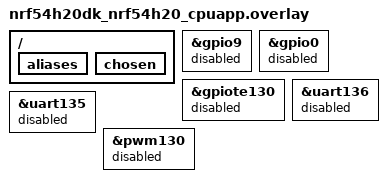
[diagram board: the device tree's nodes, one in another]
/*
 * Copyright (c) 2024 Nordic Semiconductor ASA
 *
 * SPDX-License-Identifier: LicenseRef-Nordic-5-Clause
 */


/delete-node/ &led0;
/delete-node/ &led1;
/delete-node/ &led2;
/delete-node/ &led3;
// /delete-node/ &pwmleds;

/{
	aliases {
		/delete-property/ led0;
		/delete-property/ led1;
		/delete-property/ led2;
		/delete-property/ led3;
	};

	chosen {
		/delete-property/ zephyr,console;
	};
};

&gpio9 {
	status = "disabled";
};

&gpio0 {
	status = "disabled";
};

&gpiote130 {
	status = "disabled";
};

&uart136 {
	status = "disabled";
};

&uart135 {
	status = "disabled";
};

&pwm130 {
	status = "disabled";
};
